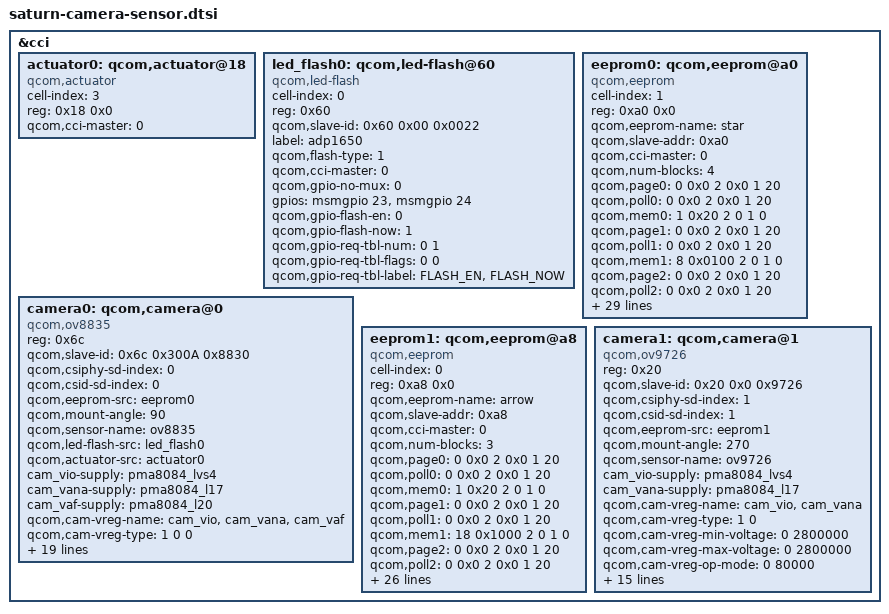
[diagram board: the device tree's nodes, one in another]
/*
 * Copyright (c) 2012-2013, The Linux Foundation. All rights reserved.
 *
 * This program is free software; you can redistribute it and/or modify
 * it under the terms of the GNU General Public License version 2 and
 * only version 2 as published by the Free Software Foundation.
 *
 * This program is distributed in the hope that it will be useful,
 * but WITHOUT ANY WARRANTY; without even the implied warranty of
 * MERCHANTABILITY or FITNESS FOR A PARTICULAR PURPOSE.  See the
 * GNU General Public License for more details.
 */

&cci {
/* back camera */
	actuator0: qcom,actuator@18 {
		cell-index = <3>;
		reg = <0x18 0x0>;
		compatible = "qcom,actuator";
		qcom,cci-master = <0>;
	};

        led_flash0: qcom,led-flash@60 {
                compatible = "qcom,led-flash";
                cell-index = <0>;
                reg = <0x60>;
                qcom,slave-id = <0x60 0x00 0x0022>;
                label = "adp1650";
                qcom,flash-type = <1>;
                qcom,cci-master = <0>;
                qcom,gpio-no-mux = <0>;
                gpios = <&msmgpio 23 0>,
                        <&msmgpio 24 0>;
                qcom,gpio-flash-en = <0>;
                qcom,gpio-flash-now = <1>;
                qcom,gpio-req-tbl-num = <0 1>;
                qcom,gpio-req-tbl-flags = <0 0>;
                qcom,gpio-req-tbl-label = "FLASH_EN",
                        "FLASH_NOW";
        };

	eeprom0: qcom,eeprom@a0 {
		cell-index = <1>;
		reg = <0xa0 0x0>;
		qcom,eeprom-name = "star";
		compatible = "qcom,eeprom";
		qcom,slave-addr = <0xa0>;
		qcom,cci-master = <0>;

		qcom,num-blocks = <4>;
                qcom,page0 = <0 0x0 2 0x0 1 20>;
                qcom,poll0 = <0 0x0 2 0x0 1 20>;
                qcom,mem0 = <1 0x20 2 0 1 0>;
                qcom,page1 = <0 0x0 2 0x0 1 20>;
		qcom,poll1 = <0 0x0 2 0x0 1 20>;
		qcom,mem1 = <8 0x0100 2 0 1 0>;
		qcom,page2 = <0 0x0 2 0x0 1 20>;
		qcom,poll2 = <0 0x0 2 0x0 1 20>;
		qcom,mem2 = <18 0x1000 2 0 1 0>;
		qcom,page3 = <0 0x0 2 0x0 1 20>;
		qcom,poll3 = <0 0x0 2 0x0 1 20>;
		qcom,mem3 = <3120 0x1015 2 0 1 0>;

		cam_vio-supply = <&pma8084_lvs4>;
		cam_vana-supply = <&pma8084_l17>;
		qcom,cam-vreg-name = "cam_vio", "cam_vana";
		qcom,cam-vreg-type = <1 0>;
		qcom,cam-vreg-min-voltage = <0 2800000>;
		qcom,cam-vreg-max-voltage = <0 2800000>;
		qcom,cam-vreg-op-mode = <0 80000>;
		qcom,gpio-no-mux = <0>;
		gpios = <&msmgpio 15 0>,
			<&msmgpio 36 0>,
			<&msmgpio 35 0>;
		qcom,gpio-reset = <1>;
		qcom,gpio-standby = <2>;
		qcom,gpio-req-tbl-num = <0 1 2>;
		qcom,gpio-req-tbl-flags = <1 0 0>;
		qcom,gpio-req-tbl-label = "CAMIF_MCLK0",
					  "CAM_RESET0",
					  "CAM_STANDBY0";
		qcom,csi-lane-assign = <0x4320>;
		qcom,csi-lane-mask = <0x1F>;
		qcom,cam-power-seq-type = "sensor_vreg", "sensor_vreg",
			"sensor_gpio", "sensor_gpio" , "sensor_clk";
		qcom,cam-power-seq-val = "cam_vana", "cam_vio",
			"sensor_gpio_reset", "sensor_gpio_standby","sensor_cam_mclk";
		qcom,cam-power-seq-cfg-val = <1 1 1 1 24000000>;
		qcom,cam-power-seq-delay = <1 1 30 30 5>;
	};

	camera0: qcom,camera@0 {
		compatible = "qcom,ov8835";
		reg = <0x6c>;
		qcom,slave-id = <0x6c 0x300A 0x8830>;
		qcom,csiphy-sd-index = <0>;
		qcom,csid-sd-index = <0>;
		qcom,eeprom-src = <&eeprom0>;
		qcom,mount-angle = <90>;
		qcom,sensor-name = "ov8835";
		qcom,led-flash-src = <&led_flash0>;
	        qcom,actuator-src=<&actuator0>;
		cam_vio-supply = <&pma8084_lvs4>;
		cam_vana-supply = <&pma8084_l17>;
		cam_vaf-supply = <&pma8084_l20>;
		qcom,cam-vreg-name = "cam_vio", "cam_vana",
					     "cam_vaf";
		qcom,cam-vreg-type = <1 0 0>;
		qcom,cam-vreg-min-voltage = <0 2800000 2950000>;
		qcom,cam-vreg-max-voltage = <0 2800000 2950000>;
		qcom,cam-vreg-op-mode = <0 80000 100000>;
		qcom,gpio-no-mux = <0>;
		gpios = <&msmgpio 15 0>,
			<&msmgpio 36 0>,
			<&msmgpio 35 0>;
		qcom,gpio-reset = <1>;
		qcom,gpio-standby = <2>;
		qcom,gpio-req-tbl-num = <0 1 2>;
		qcom,gpio-req-tbl-flags = <1 0 0>;
		qcom,gpio-req-tbl-label = "CAMIF_MCLK",
					  "CAM_RESET",
					  "CAM_PW_DN";
		qcom,gpio-set-tbl-num = <1 1 2 2>;
		qcom,gpio-set-tbl-flags = <0 2 0 2>;
		qcom,gpio-set-tbl-delay = <1000 30000 1000 30000>;
		qcom,csi-lane-assign = <0x4320>;
		qcom,csi-lane-mask = <0x1F>;
		qcom,sensor-position = <0>;
		qcom,sensor-mode = <0>;
		qcom,cci-master = <0>;
		status = "ok";
		};

/* Front camera */

	/* front camera eeprom(arrow) */
	eeprom1: qcom,eeprom@a8 {
		cell-index = <0>;
			reg = <0xa8 0x0>;
		qcom,eeprom-name = "arrow";
		compatible = "qcom,eeprom";
		qcom,slave-addr = <0xa8>;
		qcom,cci-master = <0>;

		qcom,num-blocks = <3>;
		qcom,page0 = <0 0x0 2 0x0 1 20>;
                qcom,poll0 = <0 0x0 2 0x0 1 20>;
                qcom,mem0 = <1 0x20 2 0 1 0>;
                qcom,page1 = <0 0x0 2 0x0 1 20>;
		qcom,poll1 = <0 0x0 2 0x0 1 20>;
		qcom,mem1 = <18 0x1000 2 0 1 0>;
		qcom,page2 = <0 0x0 2 0x0 1 20>;
		qcom,poll2 = <0 0x0 2 0x0 1 20>;
		qcom,mem2 = <3120 0x1015 2 0 1 0>;

		cam_vana-supply = <&pma8084_l17>;
		cam_vdig-supply = <&pma8084_l15>;
		cam_vio-supply = <&pma8084_lvs4>;
		qcom,cam-vreg-name =  "cam_vana", "cam_vdig", "cam_vio";
		qcom,cam-vreg-type = <0 0 1>;
		qcom,cam-vreg-min-voltage = <2800000 1200000 0>;
		qcom,cam-vreg-max-voltage = <2800000 1200000 0>;
		qcom,cam-vreg-op-mode = <80000 105000 0>;
		qcom,gpio-no-mux = <0>;
		gpios = <&msmgpio 17 0>,
			<&msmgpio 25 0>,
			<&msmgpio 120 0>;
		qcom,gpio-reset = <1>;
		qcom,gpio-standby = <2>;
		qcom,gpio-req-tbl-num = <0 1 2>;
		qcom,gpio-req-tbl-flags = <1 0 0>;
		qcom,gpio-req-tbl-label = "CAMIF_MCLK2",
					  "CAM_RESET2",
					  "CAM_STANDBY2";

		qcom,cam-power-seq-type = "sensor_vreg", "sensor_vreg", "sensor_vreg",
			"sensor_gpio", "sensor_gpio" , "sensor_clk";
		qcom,cam-power-seq-val = "cam_vdig", "cam_vana", "cam_vio",
			"sensor_gpio_reset", "sensor_gpio_standby","sensor_cam_mclk";
		qcom,cam-power-seq-cfg-val = <1 1 1 1 1 24000000>;
		qcom,cam-power-seq-delay = <1 1 1 30 30 5>;
	};

	camera1: qcom,camera@1 {
		compatible = "qcom,ov9726";
		reg = <0x20>;
		qcom,slave-id = <0x20 0x0 0x9726>;
		qcom,csiphy-sd-index = <1>;
		qcom,csid-sd-index = <1>;
		qcom,eeprom-src = <&eeprom1>;
		qcom,mount-angle = <270>;
		qcom,sensor-name = "ov9726";
		cam_vio-supply = <&pma8084_lvs4>;
		cam_vana-supply = <&pma8084_l17>;
		qcom,cam-vreg-name = "cam_vio", "cam_vana";
		qcom,cam-vreg-type = <1 0>;
		qcom,cam-vreg-min-voltage = <0 2800000>;
		qcom,cam-vreg-max-voltage = <0 2800000>;
		qcom,cam-vreg-op-mode = <0 80000>;
		qcom,gpio-no-mux = <0>;
		gpios = <&msmgpio 17 0>,
			<&msmgpio 25 0>,
			<&msmgpio 65 0>;
		qcom,gpio-reset = <1>;
		qcom,gpio-req-tbl-num = <0 1 2>;
		qcom,gpio-req-tbl-flags = <1 0 0>;
		qcom,gpio-req-tbl-label = "CAMIF_MCLK",
					  "CAM_RESET1",
					  "CAM_PW_DN";
		qcom,gpio-set-tbl-num = <1 1 2 2>;
		qcom,gpio-set-tbl-flags = <0 2 0 0>;
		qcom,gpio-set-tbl-delay = <1000 4000 1000 4000>;
		qcom,csi-lane-assign = <0x4320>;
		qcom,csi-lane-mask = <0x3>;
		qcom,sensor-position = <1>;
		qcom,sensor-mode = <1>;
		qcom,cci-master = <0>;
		status = "ok";
		};
};
